AUTOSAR XML (schema 00048)
package /ComponentTypes
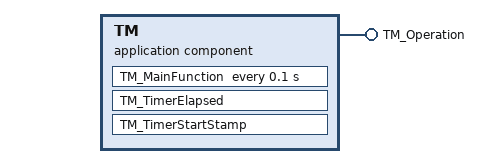
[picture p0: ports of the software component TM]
  application sw component type TM
    provide port TM_Operation: provided-com-specs=[{operation=TM_TimerElapsed, queue-length=1}, {operation=TM_TimerStartStamp, queue-length=1}], provided-interface=TM_Operation
    behavior TM_InternalBehavior
      operation invoked event OIT_TM_Operation_TM_TimerElapsed_TM_Operation_TM_TimerElapsed: start-on-event=TM_TimerElapsed, operation=TM_Operation.TM_TimerElapsed
      operation invoked event OIT_TM_Operation_TM_TimerStartStamp_TM_Operation_TM_TimerStartStamp: start-on-event=TM_TimerStartStamp, operation=TM_Operation.TM_TimerStartStamp
      timing event TMT_TM_MainFunction: start-on-event=TM_MainFunction, period=0.1
      runnable TM_TimerElapsed
      runnable TM_TimerStartStamp
      runnable TM_MainFunction
  swc implementation TM_Implementation: behavior=TM_InternalBehavior
